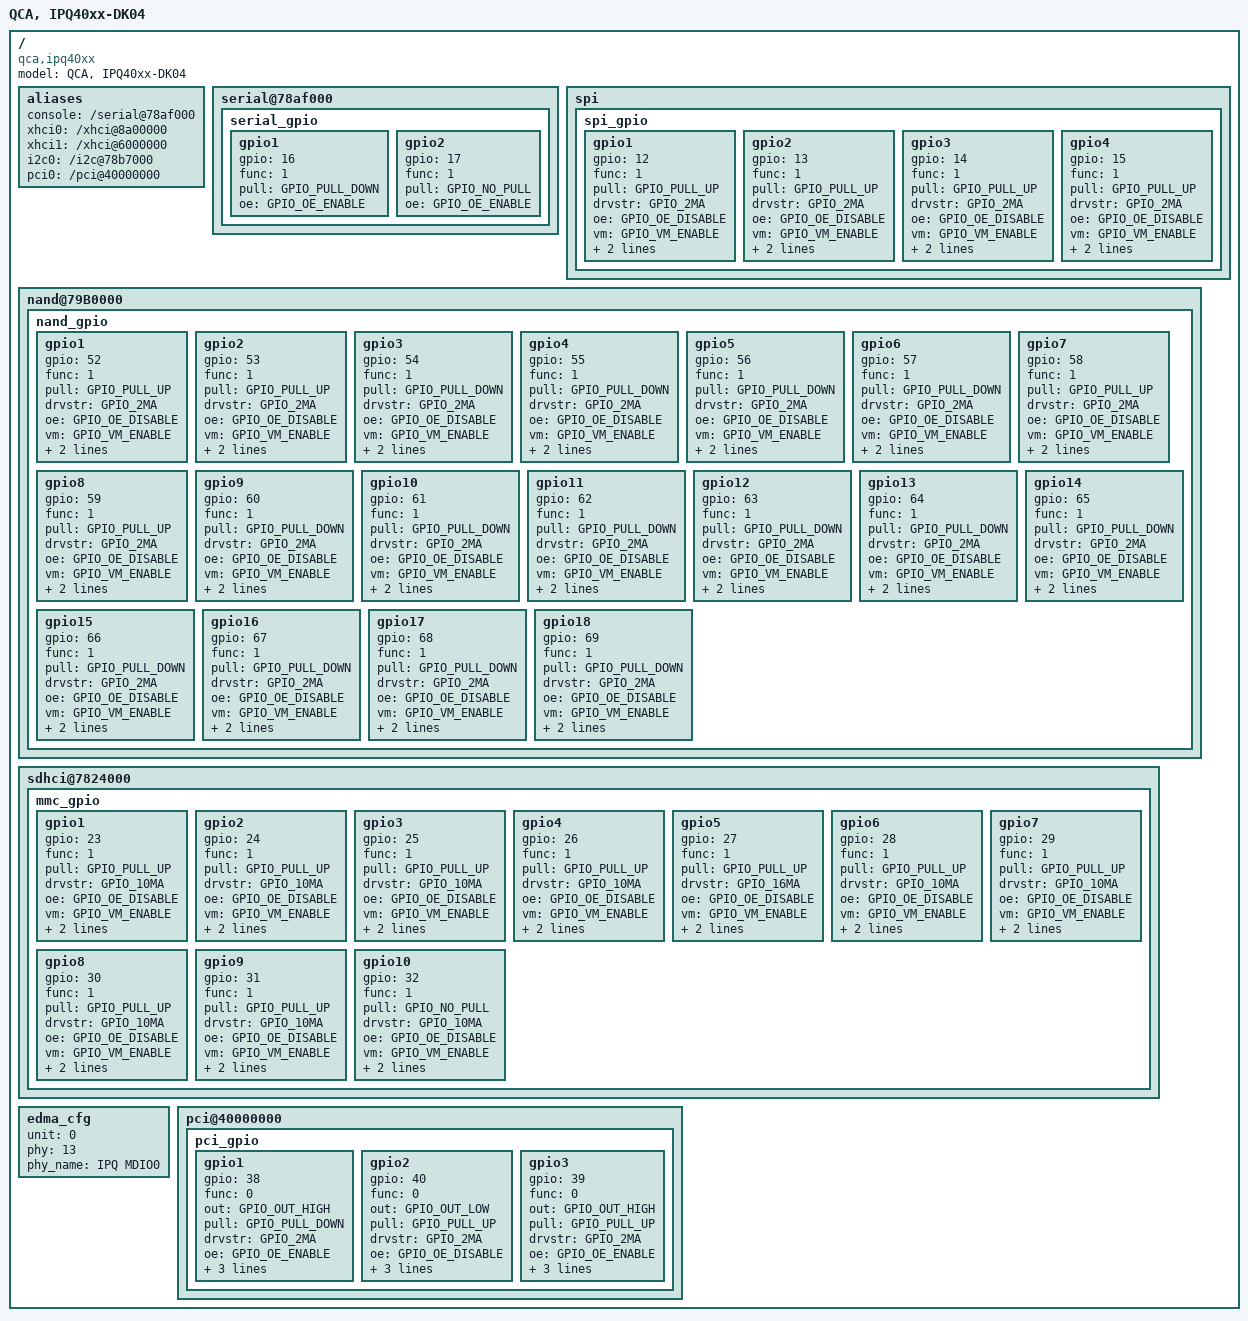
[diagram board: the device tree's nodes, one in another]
/*
 * Copyright (c) 2016, The Linux Foundation. All rights reserved.
 *
 * This program is free software; you can redistribute it and/or modify
 * it under the terms of the GNU General Public License version 2 and
 * only version 2 as published by the Free Software Foundation.
 *
 * This program is distributed in the hope that it will be useful,
 * but WITHOUT ANY WARRANTY; without even the implied warranty of
 * MERCHANTABILITY or FITNESS FOR A PARTICULAR PURPOSE.  See the
 * GNU General Public License for more details.
 */

#include "ipq40xx-soc.dtsi"
#include <dt-bindings/qcom/gpio-ipq40xx.h>
/ {
	model ="QCA, IPQ40xx-DK04";
	compatible = "qca,ipq40xx", "qca,ipq40xx-dk04";

	aliases {
		console = "/serial@78af000";
		xhci0 = "/xhci@8a00000";
		xhci1 = "/xhci@6000000";
		i2c0 = "/i2c@78b7000";
		pci0 = "/pci@40000000";
	};

	serial@78af000 {
		serial_gpio {
			gpio1 {
				gpio = <16>;
				func = <1>;
				pull = <GPIO_PULL_DOWN>;
				oe = <GPIO_OE_ENABLE>;
			};

			gpio2 {
				gpio = <17>;
				func = <1>;
				pull = <GPIO_NO_PULL>;
				oe = <GPIO_OE_ENABLE>;
			};
		};
	};

	spi {
		status = "ok";
		spi_gpio {
			gpio1 {
				gpio = <12>;
				func = <1>;
				pull = <GPIO_PULL_UP>;
				drvstr = <GPIO_2MA>;
				oe = <GPIO_OE_DISABLE>;
				vm = <GPIO_VM_ENABLE>;
				od_en = <GPIO_OD_DISABLE>;
				pu_res = <GPIO_PULL_RES2>;
			};

			gpio2 {
				gpio = <13>;
				func = <1>;
				pull = <GPIO_PULL_UP>;
				drvstr = <GPIO_2MA>;
				oe = <GPIO_OE_DISABLE>;
				vm = <GPIO_VM_ENABLE>;
				od_en = <GPIO_OD_DISABLE>;
				pu_res = <GPIO_PULL_RES2>;
			};

			gpio3 {
				gpio = <14>;
				func = <1>;
				pull = <GPIO_PULL_UP>;
				drvstr = <GPIO_2MA>;
				oe = <GPIO_OE_DISABLE>;
				vm = <GPIO_VM_ENABLE>;
				od_en = <GPIO_OD_DISABLE>;
				pu_res = <GPIO_PULL_RES2>;
			};

			gpio4 {
				gpio = <15>;
				func = <1>;
				pull = <GPIO_PULL_UP>;
				drvstr = <GPIO_2MA>;
				oe = <GPIO_OE_DISABLE>;
				vm = <GPIO_VM_ENABLE>;
				od_en = <GPIO_OD_DISABLE>;
				pu_res = <GPIO_PULL_RES2>;
			};
		};
	};

	nand@79B0000 {
		status = "ok";
		nand_gpio {
			gpio1 {
				gpio = <52>;
				func = <1>;
				pull = <GPIO_PULL_UP>;
				drvstr = <GPIO_2MA>;
				oe = <GPIO_OE_DISABLE>;
				vm = <GPIO_VM_ENABLE>;
				od_en = <GPIO_OD_DISABLE>;
				pu_res = <GPIO_PULL_RES2>;
			};

			gpio2 {
				gpio = <53>;
				func = <1>;
				pull = <GPIO_PULL_UP>;
				drvstr = <GPIO_2MA>;
				oe = <GPIO_OE_DISABLE>;
				vm = <GPIO_VM_ENABLE>;
				od_en = <GPIO_OD_DISABLE>;
				pu_res = <GPIO_PULL_RES2>;
			};

			gpio3 {
				gpio = <54>;
				func = <1>;
				pull = <GPIO_PULL_DOWN>;
				drvstr = <GPIO_2MA>;
				oe = <GPIO_OE_DISABLE>;
				vm = <GPIO_VM_ENABLE>;
				od_en = <GPIO_OD_DISABLE>;
				pu_res = <GPIO_PULL_RES2>;
			};

			gpio4 {
				gpio = <55>;
				func = <1>;
				pull = <GPIO_PULL_DOWN>;
				drvstr = <GPIO_2MA>;
				oe = <GPIO_OE_DISABLE>;
				vm = <GPIO_VM_ENABLE>;
				od_en = <GPIO_OD_DISABLE>;
				pu_res = <GPIO_PULL_RES2>;
			};

			gpio5 {
				gpio = <56>;
				func = <1>;
				pull = <GPIO_PULL_DOWN>;
				drvstr = <GPIO_2MA>;
				oe = <GPIO_OE_DISABLE>;
				vm = <GPIO_VM_ENABLE>;
				od_en = <GPIO_OD_DISABLE>;
				pu_res = <GPIO_PULL_RES2>;
			};

			gpio6 {
				gpio = <57>;
				func = <1>;
				pull = <GPIO_PULL_DOWN>;
				drvstr = <GPIO_2MA>;
				oe = <GPIO_OE_DISABLE>;
				vm = <GPIO_VM_ENABLE>;
				od_en = <GPIO_OD_DISABLE>;
				pu_res = <GPIO_PULL_RES2>;
			};

			gpio7 {
				gpio = <58>;
				func = <1>;
				pull = <GPIO_PULL_UP>;
				drvstr = <GPIO_2MA>;
				oe = <GPIO_OE_DISABLE>;
				vm = <GPIO_VM_ENABLE>;
				od_en = <GPIO_OD_DISABLE>;
				pu_res = <GPIO_PULL_RES2>;
			};

			gpio8 {
				gpio = <59>;
				func = <1>;
				pull = <GPIO_PULL_UP>;
				drvstr = <GPIO_2MA>;
				oe = <GPIO_OE_DISABLE>;
				vm = <GPIO_VM_ENABLE>;
				od_en = <GPIO_OD_DISABLE>;
				pu_res = <GPIO_PULL_RES2>;
			};

			gpio9 {
				gpio = <60>;
				func = <1>;
				pull = <GPIO_PULL_DOWN>;
				drvstr = <GPIO_2MA>;
				oe = <GPIO_OE_DISABLE>;
				vm = <GPIO_VM_ENABLE>;
				od_en = <GPIO_OD_DISABLE>;
				pu_res = <GPIO_PULL_RES2>;
			};

			gpio10 {
				gpio = <61>;
				func = <1>;
				pull = <GPIO_PULL_DOWN>;
				drvstr = <GPIO_2MA>;
				oe = <GPIO_OE_DISABLE>;
				vm = <GPIO_VM_ENABLE>;
				od_en = <GPIO_OD_DISABLE>;
				pu_res = <GPIO_PULL_RES2>;
			};

			gpio11 {
				gpio = <62>;
				func = <1>;
				pull = <GPIO_PULL_DOWN>;
				drvstr = <GPIO_2MA>;
				oe = <GPIO_OE_DISABLE>;
				vm = <GPIO_VM_ENABLE>;
				od_en = <GPIO_OD_DISABLE>;
				pu_res = <GPIO_PULL_RES2>;
			};

			gpio12 {
				gpio = <63>;
				func = <1>;
				pull = <GPIO_PULL_DOWN>;
				drvstr = <GPIO_2MA>;
				oe = <GPIO_OE_DISABLE>;
				vm = <GPIO_VM_ENABLE>;
				od_en = <GPIO_OD_DISABLE>;
				pu_res = <GPIO_PULL_RES2>;
			};

			gpio13 {
				gpio = <64>;
				func = <1>;
				pull = <GPIO_PULL_DOWN>;
				drvstr = <GPIO_2MA>;
				oe = <GPIO_OE_DISABLE>;
				vm = <GPIO_VM_ENABLE>;
				od_en = <GPIO_OD_DISABLE>;
				pu_res = <GPIO_PULL_RES2>;
			};

			gpio14 {
				gpio = <65>;
				func = <1>;
				pull = <GPIO_PULL_DOWN>;
				drvstr = <GPIO_2MA>;
				oe = <GPIO_OE_DISABLE>;
				vm = <GPIO_VM_ENABLE>;
				od_en = <GPIO_OD_DISABLE>;
				pu_res = <GPIO_PULL_RES2>;
			};

			gpio15 {
				gpio = <66>;
				func = <1>;
				pull = <GPIO_PULL_DOWN>;
				drvstr = <GPIO_2MA>;
				oe = <GPIO_OE_DISABLE>;
				vm = <GPIO_VM_ENABLE>;
				od_en = <GPIO_OD_DISABLE>;
				pu_res = <GPIO_PULL_RES2>;
			};

			gpio16 {
				gpio = <67>;
				func = <1>;
				pull = <GPIO_PULL_DOWN>;
				drvstr = <GPIO_2MA>;
				oe = <GPIO_OE_DISABLE>;
				vm = <GPIO_VM_ENABLE>;
				od_en = <GPIO_OD_DISABLE>;
				pu_res = <GPIO_PULL_RES2>;
			};

			gpio17 {
				gpio = <68>;
				func = <1>;
				pull = <GPIO_PULL_DOWN>;
				drvstr = <GPIO_2MA>;
				oe = <GPIO_OE_DISABLE>;
				vm = <GPIO_VM_ENABLE>;
				od_en = <GPIO_OD_DISABLE>;
				pu_res = <GPIO_PULL_RES2>;
			};

			gpio18 {
				gpio = <69>;
				func = <1>;
				pull = <GPIO_PULL_DOWN>;
				drvstr = <GPIO_2MA>;
				oe = <GPIO_OE_DISABLE>;
				vm = <GPIO_VM_ENABLE>;
				od_en = <GPIO_OD_DISABLE>;
				pu_res = <GPIO_PULL_RES2>;
			};
		};
	};

	sdhci@7824000 {
		mmc_gpio {
			gpio1 {
				gpio = <23>;
				func = <1>;
				pull = <GPIO_PULL_UP>;
				drvstr = <GPIO_10MA>;
				oe = <GPIO_OE_DISABLE>;
				vm = <GPIO_VM_ENABLE>;
				od_en = <GPIO_OD_DISABLE>;
				pu_res = <GPIO_PULL_RES2>;
			};

			gpio2 {
				gpio = <24>;
				func = <1>;
				pull = <GPIO_PULL_UP>;
				drvstr = <GPIO_10MA>;
				oe = <GPIO_OE_DISABLE>;
				vm = <GPIO_VM_ENABLE>;
				od_en = <GPIO_OD_DISABLE>;
				pu_res = <GPIO_PULL_RES2>;
			};

			gpio3 {
				gpio = <25>;
				func = <1>;
				pull = <GPIO_PULL_UP>;
				drvstr = <GPIO_10MA>;
				oe = <GPIO_OE_DISABLE>;
				vm = <GPIO_VM_ENABLE>;
				od_en = <GPIO_OD_DISABLE>;
				pu_res = <GPIO_PULL_RES2>;
			};

			gpio4 {
				gpio = <26>;
				func = <1>;
				pull = <GPIO_PULL_UP>;
				drvstr = <GPIO_10MA>;
				oe = <GPIO_OE_DISABLE>;
				vm = <GPIO_VM_ENABLE>;
				od_en = <GPIO_OD_DISABLE>;
				pu_res = <GPIO_PULL_RES2>;
			};

			gpio5 {
				gpio = <27>;
				func = <1>;
				pull = <GPIO_PULL_UP>;
				drvstr = <GPIO_16MA>;
				oe = <GPIO_OE_DISABLE>;
				vm = <GPIO_VM_ENABLE>;
				od_en = <GPIO_OD_DISABLE>;
				pu_res = <GPIO_PULL_RES2>;
			};

			gpio6 {
				gpio = <28>;
				func = <1>;
				pull = <GPIO_PULL_UP>;
				drvstr = <GPIO_10MA>;
				oe = <GPIO_OE_DISABLE>;
				vm = <GPIO_VM_ENABLE>;
				od_en = <GPIO_OD_DISABLE>;
				pu_res = <GPIO_PULL_RES2>;
			};

			gpio7 {
				gpio = <29>;
				func = <1>;
				pull = <GPIO_PULL_UP>;
				drvstr = <GPIO_10MA>;
				oe = <GPIO_OE_DISABLE>;
				vm = <GPIO_VM_ENABLE>;
				od_en = <GPIO_OD_DISABLE>;
				pu_res = <GPIO_PULL_RES2>;
			};

			gpio8 {
				gpio = <30>;
				func = <1>;
				pull = <GPIO_PULL_UP>;
				drvstr = <GPIO_10MA>;
				oe = <GPIO_OE_DISABLE>;
				vm = <GPIO_VM_ENABLE>;
				od_en = <GPIO_OD_DISABLE>;
				pu_res = <GPIO_PULL_RES2>;
			};

			gpio9 {
				gpio = <31>;
				func = <1>;
				pull = <GPIO_PULL_UP>;
				drvstr = <GPIO_10MA>;
				oe = <GPIO_OE_DISABLE>;
				vm = <GPIO_VM_ENABLE>;
				od_en = <GPIO_OD_DISABLE>;
				pu_res = <GPIO_PULL_RES2>;
			};

			gpio10 {
				gpio = <32>;
				func = <1>;
				pull = <GPIO_NO_PULL>;
				drvstr = <GPIO_10MA>;
				oe = <GPIO_OE_DISABLE>;
				vm = <GPIO_VM_ENABLE>;
				od_en = <GPIO_OD_DISABLE>;
				pu_res = <GPIO_PULL_RES2>;
			};
		};
	};

	edma_cfg {
		unit = <0>;
		/* Based on the enum for PSGMII phy interface from include/phy.h */
		phy = <13>;
		phy_name = "IPQ MDIO0";
	};

	pci@40000000 {
		pci_gpio {
			gpio1 {
				gpio = <38>;
				func = <0>;
				out = <GPIO_OUT_HIGH>;
				pull = <GPIO_PULL_DOWN>;
				drvstr = <GPIO_2MA>;
				oe = <GPIO_OE_ENABLE>;
				vm = <GPIO_VM_ENABLE>;
				od_en = <GPIO_OD_DISABLE>;
				pu_res = <GPIO_PULL_RES2>;
			};

			gpio2 {
				gpio = <40>;
				func = <0>;
				out = <GPIO_OUT_LOW>;
				pull = <GPIO_PULL_UP>;
				drvstr = <GPIO_2MA>;
				oe = <GPIO_OE_DISABLE>;
				vm = <GPIO_VM_ENABLE>;
				od_en = <GPIO_OD_DISABLE>;
				pu_res = <GPIO_PULL_RES2>;
			};

			gpio3 {
				gpio = <39>;
				func = <0>;
				out = <GPIO_OUT_HIGH>;
				pull = <GPIO_PULL_UP>;
				drvstr = <GPIO_2MA>;
				oe = <GPIO_OE_ENABLE>;
				vm = <GPIO_VM_ENABLE>;
				od_en = <GPIO_OD_DISABLE>;
				pu_res = <GPIO_PULL_RES2>;
			};
		};
	};
};

